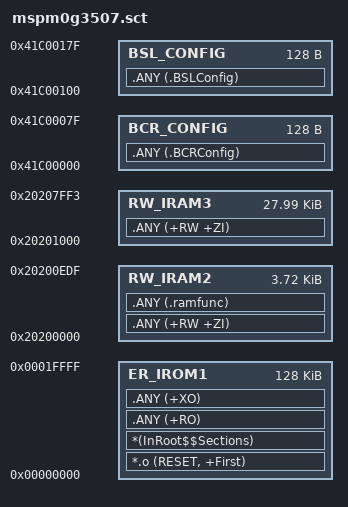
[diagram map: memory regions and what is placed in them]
; *************************************************************
; *** Scatter-Loading Description File generated by uVision ***
; *************************************************************

LR_IROM1 0x00000000 0x00020000  {    ; load region size_region
  ER_IROM1 0x00000000 ALIGNALL 8 0x00020000  {  ; load address = execution address
   *.o (RESET, +First)
   *(InRoot$$Sections)
   .ANY (+RO)
   .ANY (+XO)
  }
; This example implements a workaround for BSL_ERR_01.
; The following SRAM locations should not be used when using non-ECC SRAM
; and the application needs to jump to BSL:
;       0x2020_0EE0 - 0x2020_0FFF
;       0x2020_7FF4 - 0x2020_8000
;
  RW_IRAM2 0x20200000 0x00000EE0  {  ; RW data
   .ANY (+RW +ZI)
   .ANY (.ramfunc)
  }
  RW_IRAM3 0x20201000 0x00006FF4  {  ; RW data
   .ANY (+RW +ZI)
  }
}

LR_BCR 0x41C00000 0x00000100  {    ; load region size_region
  BCR_CONFIG 0x41C00000 0x00000080{
	.ANY (.BCRConfig)
  }
}

LR_BSL 0x41C00100 0x00000100  {    ; load region size_region
   BSL_CONFIG 0x41C00100 0x00000080{
	.ANY (.BSLConfig)
  }
}
